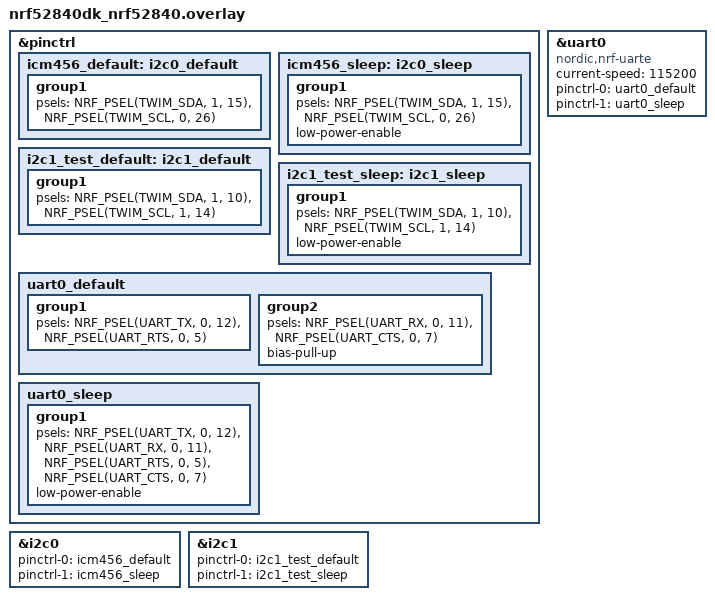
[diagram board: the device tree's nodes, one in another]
&pinctrl {
    icm456_default: i2c0_default {
        group1 {
            psels = <NRF_PSEL(TWIM_SDA, 1, 15)>,
                <NRF_PSEL(TWIM_SCL, 0, 26)>;
        };
    };
    
    icm456_sleep: i2c0_sleep {
        group1 {
            psels = <NRF_PSEL(TWIM_SDA, 1, 15)>,
                <NRF_PSEL(TWIM_SCL, 0, 26)>;
            low-power-enable;
        };
    };

    i2c1_test_default: i2c1_default {
		group1 {
			psels = <NRF_PSEL(TWIM_SDA, 1, 10)>,
				<NRF_PSEL(TWIM_SCL, 1, 14)>;
			// psels = <NRF_PSEL(TWIM_SDA, 1, 15)>,
			// <NRF_PSEL(TWIM_SCL, 0, 26)>;
		};
	};

	i2c1_test_sleep: i2c1_sleep {
		group1 {
			psels = <NRF_PSEL(TWIM_SDA, 1, 10)>,
				<NRF_PSEL(TWIM_SCL, 1, 14)>;
			// psels = <NRF_PSEL(TWIM_SDA, 1, 15)>,
			// <NRF_PSEL(TWIM_SCL, 0, 26)>;
			low-power-enable;
		};
	};

    uart0_default: uart0_default {
		group1 {
			psels = <NRF_PSEL(UART_TX, 0, 12)>,
				<NRF_PSEL(UART_RTS, 0, 5)>;
		};
		group2 {
			psels = <NRF_PSEL(UART_RX, 0, 11)>,
				<NRF_PSEL(UART_CTS, 0, 7)>;
			bias-pull-up;
		};
	};

	uart0_sleep: uart0_sleep {
		group1 {
			psels = <NRF_PSEL(UART_TX, 0, 12)>,
				<NRF_PSEL(UART_RX, 0, 11)>,
				<NRF_PSEL(UART_RTS, 0, 5)>,
				<NRF_PSEL(UART_CTS, 0, 7)>;
			low-power-enable;
		};
    };
};

&i2c0 {
    pinctrl-0 = <&icm456_default>;
    pinctrl-1 = <&icm456_sleep>;
    pinctrl-names = "default", "sleep";
};

&i2c1 {
    status = "okay";
	pinctrl-0 = <&i2c1_test_default>;
	pinctrl-1 = <&i2c1_test_sleep>;
	pinctrl-names = "default", "sleep";
};

&uart0 {
	compatible = "nordic,nrf-uarte";
	status = "okay";
	current-speed = <115200>;
	pinctrl-0 = <&uart0_default>;
	pinctrl-1 = <&uart0_sleep>;
	pinctrl-names = "default", "sleep";
};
